# CM41x_M4 register map
Vendor: Analog Devices; Series: CM41x_M4; File version: 1p0
CPU: CM4 r0p1, little endian, MPU, FPU, 4 interrupt priority bits
Registers are 32-bit, read-write, reset 0x0 unless marked. A register's access mark holds for its fields unless they carry their own. Offsets are from the block's base; [hi:lo] are bit positions; <NAME> marks a mode.

## FLC0 — Flash Controller
Base 0xF8010000
Same registers: FLC1 0xF8011000
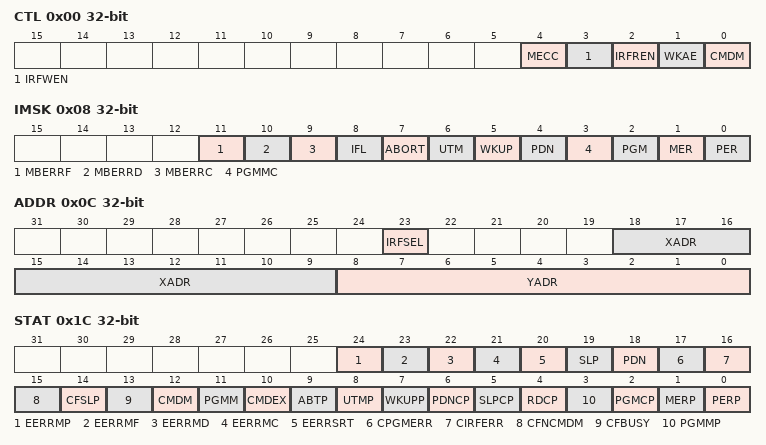
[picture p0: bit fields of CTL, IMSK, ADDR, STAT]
0x00 CTL — Control Register
  [4] MECC range 0x00000000..0x00000001 — Manual ECC Mode
  [3] IRFWEN range 0x00000000..0x00000001 — Information block Write Enable
  [2] IRFREN range 0x00000000..0x00000001 — Information block Read Enable
  [1] WKAE range 0x00000000..0x00000001 — Wake on access enable
  [0] CMDM range 0x00000000..0x00000001 — Command Mode
0x04 CMD — Command Register
  [3:0] FLCMDS — Flash Controller Commands
    1=PER (Page Erase Command (PER).); 2=MER (Mass Erase command (MER).); 3=PGMC (Program command (PGMC).); 4=SPGMM (Start Program Mode (SPGMM).); 5=EPGMM (End Program Mode (EPGMM).); 6=RDC (Read Command (RDC).); 7=SLPC (Sleep command (SLPC).); 8=WKSL (Wakeup from sleep (WKSL).); 11=UTM (Update timing info (UTM).); 15=ABORT (Abort the current command (ABORT).)
0x08 IMSK — Interrupt Enable Register
  [11] MBERRF range 0x00000000..0x00000001 — Command Read Multi Bit Error
  [10] MBERRD range 0x00000000..0x00000001 — Multi bit error DMA
  [9] MBERRC range 0x00000000..0x00000001 — Multi bit error in core
  [8] IFL range 0x00000000..0x00000001 — Improper Flash Command
  [7] ABORT range 0x00000000..0x00000001 — Abort command
  [6] UTM range 0x00000000..0x00000001 — Update Timing Command
  [5] WKUP range 0x00000000..0x00000001 — Wakeup Command
  [4] PDN range 0x00000000..0x00000001 — Power Down command
  [3] PGMMC range 0x00000000..0x00000001 — Program Mode Change Command
  [2] PGM range 0x00000000..0x00000001 — Program command
  [1] MER range 0x00000000..0x00000001 — Mass Erase
  [0] PER range 0x00000000..0x00000001 — Page Erase
0x0C ADDR — Command Address Register
  [23] IRFSEL — Information Block Select
  [18:9] XADR range 0x00000000..0x000003FF — Row Address
  [8:0] YADR range 0x00000000..0x000001FF — Column Address
0x10 DATA0 — Command Data Register 0
  [31:0] VALUE range 0x00000000..0xFFFFFFFF — Command Data bits [31:0]
0x14 DATA1 — Command Data Register 1
  [31:0] VALUE range 0x00000000..0xFFFFFFFF — Command Data bits [63:32]
0x18 ECC — Command ECC Register
  [7:0] VALUE range 0x00000000..0x000000FF — Flash Controller ECC bits
0x1C STAT — Status Register
  [24] EERRMP range 0x00000000..0x00000001 — ECC Error Sticky Multi Bit Pre-fetcher Read
  [23] EERRMF range 0x00000000..0x00000001 — ECC Error Sticky Multi Bit - Command Reads
  [22] EERRMD range 0x00000000..0x00000001 — ECC Error Sticky Multi Bit - DMA reads
  [21] EERRMC range 0x00000000..0x00000001 — ECC Error Sticky Multi Bit - Core reads
  [20] EERRSRT range 0x00000000..0x00000001 — ECC Single Bit Correction Threshold reached - All Reads
  [19] SLP ro — Flash in Sleep State
  [18] PDN ro — Flash in Power Down State
  [17] CPGMERR range 0x00000000..0x00000001 — Command Violated Program Mode Guidelines
  [16] CIRFERR range 0x00000000..0x00000001 — Command Violated Information Block Privileges
  [15] CFNCMDM range 0x00000000..0x00000001 — Command Issued in Non Command Mode
  [14] CFSLP range 0x00000000..0x00000001 — Command Issued in Sleep Mode
  [13] CFBUSY range 0x00000000..0x00000001 — Command Issued in Busy State
  [12] CMDM ro — Controller in Command Mode
  [11] PGMM ro — Controller in Program Mode
  [10] CMDEX range 0x00000000..0x00000001 — Command Executed
  [9] ABTP ro — Abort Command Pending
  [8] UTMP ro — Update Timing Registers Pending
  [7] WKUPP ro — Wakeup Command Pending
  [6] PDNCP ro — Power Down Command Pending
  [5] SLPCP ro — Sleep Command Pending
  [4] RDCP ro — Read Command Pending
  [3] PGMMP ro — Program Mode Change Pending
  [2] PGMCP ro — Program Command Pending
  [1] MERP ro — Mass Erase Command Pending
  [0] PERP ro — Page Erase Command Pending
0x20 CMD_KEY — Command Key Register
  [15:0] VALUE range 0x00000000..0x0000FFFF — Command Key
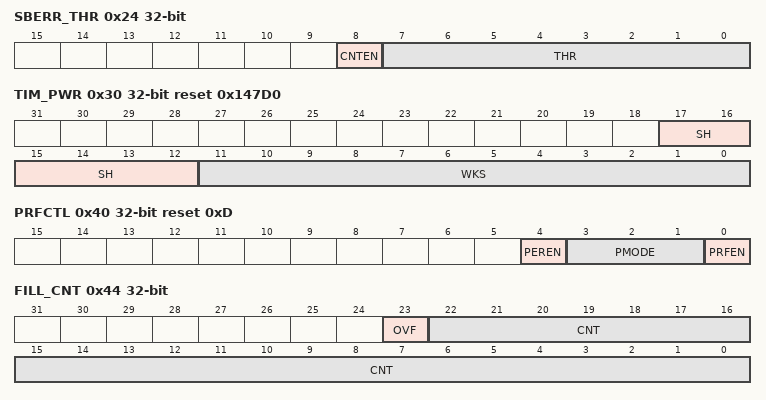
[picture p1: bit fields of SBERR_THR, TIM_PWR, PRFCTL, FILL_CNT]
0x24 SBERR_THR — ECC Single Bit Error Threshold Register
  [8] CNTEN range 0x00000000..0x00000001 — Error Counter Enable
  [7:0] THR range 0x00000000..0x000000FF — ECC Single Bit Error Threshold
0x30 TIM_PWR reset 0x147D0 — Power Timing Register
  [17:12] SH range 0x00000000..0x0000003F — Standby Hold Time
  [11:0] WKS range 0x00000000..0x00000FFF — Wakeup Time from Sleep to Standby
0x40 PRFCTL reset 0xD — Prefetch Control Register
  [4] PEREN range 0x00000000..0x00000001 — Performance Counters Enable
  [3:1] PMODE — Performance Mode
    0=A (Performance Mode A is <= 75 MHz); 2=B (Performance Mode B is 76 to 150 MHz); 4=C (Performance Mode C is 151 to 225 MHz); 6=E (Performance Mode E is 226 to 240 MHz)
  [0] PRFEN range 0x00000000..0x00000001 — Pre-fetcher Enable
0x44 FILL_CNT — Pre-fetcher Fill Count Register
  [23] OVF range 0x00000000..0x00000001 — Fill Count Overflow
  [22:0] CNT range 0x00000000..0x007FFFFF — Fill Count
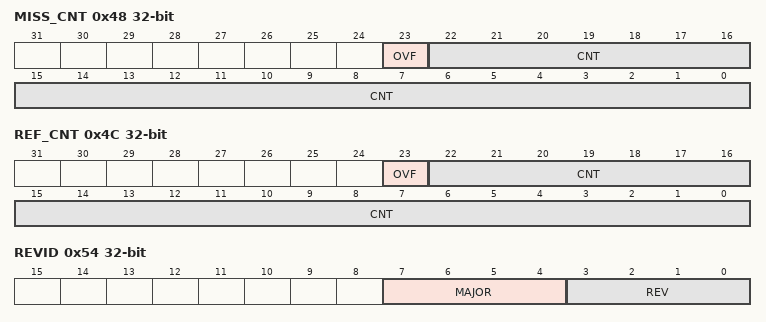
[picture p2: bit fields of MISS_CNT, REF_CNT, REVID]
0x48 MISS_CNT — Pre-fetcher Miss Count Register
  [23] OVF range 0x00000000..0x00000001 — Miss Count Overflow
  [22:0] CNT range 0x00000000..0x007FFFFF — Miss Count
0x4C REF_CNT — Pre-fetcher Reference Count Register
  [23] OVF range 0x00000000..0x00000001 — Reference Count Overflow
  [22:0] CNT range 0x00000000..0x007FFFFF — Reference Count
0x54 REVID — Revision ID Register
  [7:4] MAJOR ro — Major Revision ID
  [3:0] REV ro — Incremental Revision ID
